# ECM3531 register map
Vendor: EtaCompute; Series: ECM35xx; File version: 1.0.0
CPU: CM3 r1p1, little endian, MPU, no FPU, 3 interrupt priority bits
Registers are 32-bit, read-write, reset 0x0 unless marked. A register's access mark holds for its fields unless they carry their own. Offsets are from the block's base; [hi:lo] are bit positions.

## SOCCTRL — The system control module provides memory mapped I/O control and status for various and miscellaneous portions of the SOC.
Base 0x50030080
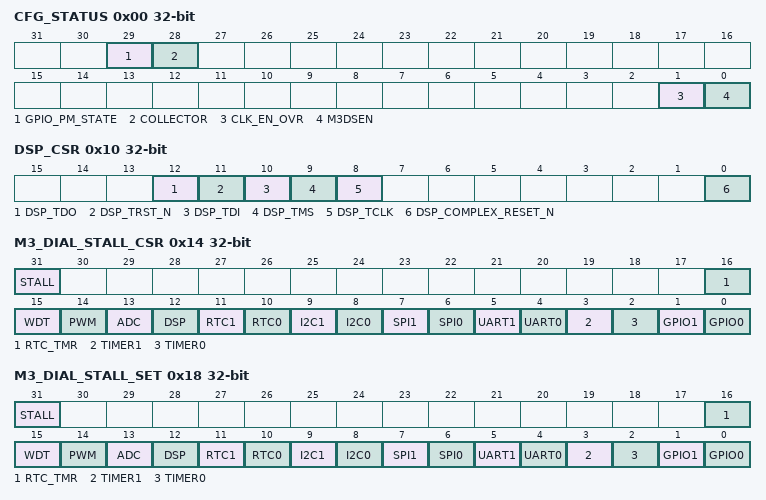
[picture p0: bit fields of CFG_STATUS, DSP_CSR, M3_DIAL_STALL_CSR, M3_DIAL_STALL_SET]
0x00 CFG_STATUS — Configuration and status bits for the SOCCTRL register.
  [29] GPIO_PM_STATE ro — Read only view of the pin state for the GPIO_PM pin. When this is one, then the chip is in one of its pin based test modes.
    0=NORMAL (Pins are all zero for normal mode. Anything else is abbienormal.); 1=ABNORMAL (Pins are in use for one of several test modes. GPIO, SPI1, SPI2, I2C1, I2C2, and UART1 do not work in this case.)
  [28] COLLECTOR ro — Read only view of internal debug state.
  [1] CLK_EN_OVR — Force the clock enable for this module ON to prevent clock gating at the HFO. Intended for debug purposes.
    1=ENABLE (Prevent HFO clock gating.); 0=DISABLE (Allow HFO clock gating when block is inactive.)
  [0] M3DSEN — Set to 1 to enable testing the whatchamacallit.
    1=ENABLE (Enable DIAL STALL of M3); 0=DISABLE (Disable DIAL STALLs for the M3 for testing.)
0x04 FLASH_CFG_STATUS — Configuration and status bits for the FLASH controller.
  [2:0] NUM_WS — Programmable number of wait states for the Flash Interface from the ARM M3.
0x08 M3_FREQ_COUNT — Provide a read only value for diagnostics.
  [31:0] COUNT ro — Debug Read Only Value M3 CLOCK frequency counter.
0x0C HFO_FREQ_COUNT — Provide a read only value for diagnostics.
  [31:0] COUNT ro — Debug Read Only Value HFO frequency counter.
0x10 DSP_CSR — Configuration and status bits for controlling the DSP.
  [12] DSP_TDO ro — Bit bang interface for DSP JTAG.
  [11] DSP_TRST_N — Bit bang interface for DSP JTAG. NOTE the inversion.
  [10] DSP_TDI — Bit bang interface for DSP JTAG.
  [9] DSP_TMS — Bit bang interface for DSP JTAG.
  [8] DSP_TCLK — Bit bang interface for DSP JTAG.
  [0] DSP_COMPLEX_RESET_N — Set to 0 to reset the DSP using the hard reset input to its DIAL block.
    0=FORCE (Force reset to the DSP.); 1=RELEASE (Release the master reset.)
0x14 M3_DIAL_STALL_CSR — Configuration and status bits for controlling DIAL stalls in the M3
  [31] STALL — Set to 1 to force the M3 into a DIAL STALL condition. In this state, the M3 is held in wait state much like clock gating sleep in conventional clocked logic. The normal NULL/DATA cycling is suspended until this flip flop is reset. It is reset upon the arrival of an enabled interrupt request to the M3, as enabled by the bits in this register. This FF can be set by the arrival of a WFI_TOGGLE from the M3 core. Use DIAL_STALL_SET and DIAL_STALL_CLR registers to manipulate this bit.
  [16] RTC_TMR — Set to 1 to enable the corresponding external interrupt to wake up the M3 core from a DIAL STALL state. Use DIAL_STALL_SET and DIAL_STALL_CLR registers to manipulate these bits.
  [15] WDT — Set to 1 to enable the corresponding external interrupt to wake up the M3 core from a DIAL STALL state. Use DIAL_STALL_SET and DIAL_STALL_CLR registers to manipulate these bits.
  [14] PWM — Set to 1 to enable the corresponding external interrupt to wake up the M3 core from a DIAL STALL state. Use DIAL_STALL_SET and DIAL_STALL_CLR registers to manipulate these bits.
  [13] ADC — Set to 1 to enable the corresponding external interrupt to wake up the M3 core from a DIAL STALL state. Use DIAL_STALL_SET and DIAL_STALL_CLR registers to manipulate these bits.
  [12] DSP — Set to 1 to enable the corresponding external interrupt to wake up the M3 core from a DIAL STALL state. Use DIAL_STALL_SET and DIAL_STALL_CLR registers to manipulate these bits.
  [11] RTC1 — Set to 1 to enable the corresponding external interrupt to wake up the M3 core from a DIAL STALL state. Use DIAL_STALL_SET and DIAL_STALL_CLR registers to manipulate these bits.
  [10] RTC0 — Set to 1 to enable the corresponding external interrupt to wake up the M3 core from a DIAL STALL state. Use DIAL_STALL_SET and DIAL_STALL_CLR registers to manipulate these bits.
  [9] I2C1 — Set to 1 to enable the corresponding external interrupt to wake up the M3 core from a DIAL STALL state. Use DIAL_STALL_SET and DIAL_STALL_CLR registers to manipulate these bits.
  [8] I2C0 — Set to 1 to enable the corresponding external interrupt to wake up the M3 core from a DIAL STALL state. Use DIAL_STALL_SET and DIAL_STALL_CLR registers to manipulate these bits.
  [7] SPI1 — Set to 1 to enable the corresponding external interrupt to wake up the M3 core from a DIAL STALL state. Use DIAL_STALL_SET and DIAL_STALL_CLR registers to manipulate these bits.
  [6] SPI0 — Set to 1 to enable the corresponding external interrupt to wake up the M3 core from a DIAL STALL state. Use DIAL_STALL_SET and DIAL_STALL_CLR registers to manipulate these bits.
  [5] UART1 — Set to 1 to enable the corresponding external interrupt to wake up the M3 core from a DIAL STALL state. Use DIAL_STALL_SET and DIAL_STALL_CLR registers to manipulate these bits.
  [4] UART0 — Set to 1 to enable the corresponding external interrupt to wake up the M3 core from a DIAL STALL state. Use DIAL_STALL_SET and DIAL_STALL_CLR registers to manipulate these bits.
  [3] TIMER1 — Set to 1 to enable the corresponding external interrupt to wake up the M3 core from a DIAL STALL state. Use DIAL_STALL_SET and DIAL_STALL_CLR registers to manipulate these bits.
  [2] TIMER0 — Set to 1 to enable the corresponding external interrupt to wake up the M3 core from a DIAL STALL state. Use DIAL_STALL_SET and DIAL_STALL_CLR registers to manipulate these bits.
  [1] GPIO1 — Set to 1 to enable the corresponding external interrupt to wake up the M3 core from a DIAL STALL state. Use DIAL_STALL_SET and DIAL_STALL_CLR registers to manipulate these bits.
  [0] GPIO0 — Set to 1 to enable the corresponding external interrupt to wake up the M3 core from a DIAL STALL state. Use DIAL_STALL_SET and DIAL_STALL_CLR registers to manipulate these bits.
0x18 M3_DIAL_STALL_SET — Bit setting for the configuration and status bits for controlling DIAL stalls in the M3
  [31] STALL wo — Set to 1 to cause the corresponding bit in the M3 DIAL STALL CSR to be set.
  [16] RTC_TMR — Set to 1 to enable the corresponding external interrupt to wake up the M3 core from a DIAL STALL state.
  [15] WDT — Set to 1 to enable the corresponding external interrupt to wake up the M3 core from a DIAL STALL state.
  [14] PWM — Set to 1 to enable the corresponding external interrupt to wake up the M3 core from a DIAL STALL state.
  [13] ADC — Set to 1 to enable the corresponding external interrupt to wake up the M3 core from a DIAL STALL state.
  [12] DSP — Set to 1 to enable the corresponding external interrupt to wake up the M3 core from a DIAL STALL state.
  [11] RTC1 — Set to 1 to enable the corresponding external interrupt to wake up the M3 core from a DIAL STALL state.
  [10] RTC0 — Set to 1 to enable the corresponding external interrupt to wake up the M3 core from a DIAL STALL state.
  [9] I2C1 — Set to 1 to enable the corresponding external interrupt to wake up the M3 core from a DIAL STALL state.
  [8] I2C0 — Set to 1 to enable the corresponding external interrupt to wake up the M3 core from a DIAL STALL state.
  [7] SPI1 — Set to 1 to enable the corresponding external interrupt to wake up the M3 core from a DIAL STALL state.
  [6] SPI0 — Set to 1 to enable the corresponding external interrupt to wake up the M3 core from a DIAL STALL state.
  [5] UART1 — Set to 1 to enable the corresponding external interrupt to wake up the M3 core from a DIAL STALL state.
  [4] UART0 — Set to 1 to enable the corresponding external interrupt to wake up the M3 core from a DIAL STALL state.
  [3] TIMER1 — Set to 1 to enable the corresponding external interrupt to wake up the M3 core from a DIAL STALL state.
  [2] TIMER0 — Set to 1 to enable the corresponding external interrupt to wake up the M3 core from a DIAL STALL state.
  [1] GPIO1 — Set to 1 to enable the corresponding external interrupt to wake up the M3 core from a DIAL STALL state.
  [0] GPIO0 — Set to 1 to enable the corresponding external interrupt to wake up the M3 core from a DIAL STALL state.
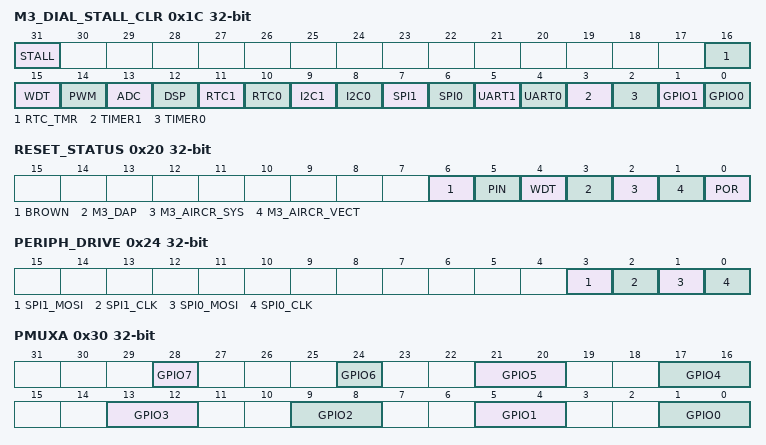
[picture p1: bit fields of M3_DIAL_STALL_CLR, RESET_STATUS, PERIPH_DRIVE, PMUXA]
0x1C M3_DIAL_STALL_CLR — Bit clearing for the configuration and status bits for controlling DIAL stalls in the M3
  [31] STALL wo — Set to 1 to cause the corresponding bit in the M3 DIAL STALL CSR to be cleared.
  [16] RTC_TMR — Set to 1 to disable the corresponding external interrupt from waking up the M3 core from a DIAL STALL state.
  [15] WDT — Set to 1 to disable the corresponding external interrupt from waking up the M3 core from a DIAL STALL state.
  [14] PWM — Set to 1 to disable the corresponding external interrupt from waking up the M3 core from a DIAL STALL state.
  [13] ADC — Set to 1 to disable the corresponding external interrupt from waking up the M3 core from a DIAL STALL state.
  [12] DSP — Set to 1 to disable the corresponding external interrupt from waking up the M3 core from a DIAL STALL state.
  [11] RTC1 — Set to 1 to disable the corresponding external interrupt from waking up the M3 core from a DIAL STALL state.
  [10] RTC0 — Set to 1 to disable the corresponding external interrupt from waking up the M3 core from a DIAL STALL state.
  [9] I2C1 — Set to 1 to disable the corresponding external interrupt from waking up the M3 core from a DIAL STALL state.
  [8] I2C0 — Set to 1 to disable the corresponding external interrupt from waking up the M3 core from a DIAL STALL state.
  [7] SPI1 — Set to 1 to disable the corresponding external interrupt from waking up the M3 core from a DIAL STALL state.
  [6] SPI0 — Set to 1 to disable the corresponding external interrupt from waking up the M3 core from a DIAL STALL state.
  [5] UART1 — Set to 1 to disable the corresponding external interrupt from waking up the M3 core from a DIAL STALL state.
  [4] UART0 — Set to 1 to disable the corresponding external interrupt from waking up the M3 core from a DIAL STALL state.
  [3] TIMER1 — Set to 1 to disable the corresponding external interrupt from waking up the M3 core from a DIAL STALL state.
  [2] TIMER0 — Set to 1 to disable the corresponding external interrupt from waking up the M3 core from a DIAL STALL state.
  [1] GPIO1 — Set to 1 to disable the corresponding external interrupt from waking up the M3 core from a DIAL STALL state.
  [0] GPIO0 — Set to 1 to disable the corresponding external interrupt from waking up the M3 core from a DIAL STALL state.
0x20 RESET_STATUS — Provide a read only view of status bits that get set by the various causes for an SOC reset. Writing anything to this register resets all the bits. The bits can accumulate so it is possible to have both the POR and M3_DAP bits set immediately after a reset caused by the debugger, for example. POR will always clear the other status bits as will writing to this regiser.
  [6] BROWN ro — Set to one if and only if a brownout reset occurred, since the last time this bit was cleared. This bit is cleared by writing anything to this register. NOTE: This is not currently implemented in the chip.
  [5] PIN ro — Set to one if and only if the hardware reset pin was asserted since the last time this bit was cleared. This bit is cleared by writing anything to this register.
  [4] WDT ro — Set to one if and only if the watchdog timer expired with reset enabled, since the last time this bit was cleared. This bit is cleared by writing anything to this register.
  [3] M3_DAP ro — Set to one if and only if the M3 DAP CSR bit in the M3 was written to 1 since the last time this bit was cleared. This bit is cleared by writing anything to this register.
  [2] M3_AIRCR_SYS ro — Set to one if and only if the AIRCR SYSTEM RESET REQUEST bit in the M3 was written to 1 since the last time this bit was cleared. This bit is cleared by writing anything to this register. This bit resets the entire chip.
  [1] M3_AIRCR_VECT ro — Set to one if and only if the AIRCR VECTOR RESET REQUEST bit in the M3 was written to 1 since the last time this bit was cleared. This bit is cleared by writing anything to this register. This bit only resets the M3 core.
  [0] POR ro — Set to one if and only if the power on reset pin was asserted since the last time this bit was cleared. This bit is cleared by writing anything to this register.
0x24 PERIPH_DRIVE — Controls the high drive strength settings for some of the dedicated pads associated with various peripherals, e.g. SPI clock.
  [3] SPI1_MOSI — Debug Read Only Value for Diagnostics.
  [2] SPI1_CLK — Debug Read Only Value for Diagnostics.
  [1] SPI0_MOSI — Debug Read Only Value for Diagnostics.
  [0] SPI0_CLK — Debug Read Only Value for Diagnostics.
0x28 FWTRACEA — Provide software driven output that can be seen on the front panel without a UART, etc.
  [31:0] VALUE — Firmware can write to this register and the results will show up on the front panel.NOTE: this register only gets cleared by the initial power on reset and not by anyother form of reset.
0x2C FWTRACEB — Provide software driven output that can be seen on the front panel without a UART, etc. NOTE: this register only gets cleared by the initial power on reset and not by anyother form of reset.
  [31:0] VALUE — Firmware can write to this register and the results will show up on the front panel.
0x30 PMUXA — This register provides control pin/pad mux for GPIO[7:0]
  [28] GPIO7 — Selects one of 4 possible uses for this pin.
    0=GPIO7 (GPIO7 in normal mode); 1=PWMCH7 (PWM Channel 7 in normal mode)
  [24] GPIO6 — Selects one of 4 possible uses for this pin.
    0=GPIO6 (GPIO6 in normal mode); 1=PWMCH6 (PWM Channel 6 in normal mode)
  [21:20] GPIO5 — Selects one of 4 possible uses for this pin.
    0=GPIO5 (GPIO5 in normal mode); 1=PWMCH5 (PWM Channel 5 in normal mode); 2=UART1DBGA (UART1 DEBUG A output in normal mode)
  [17:16] GPIO4 — Selects one of 4 possible uses for this pin.
    0=GPIO4 (GPIO4 in normal mode); 1=PWMCH4 (PWM Channel 4 in normal mode); 2=UART1DBGB (UART1 DEBUG B output in normal mode)
  [13:12] GPIO3 — Selects one of 4 possible uses for this pin.
    0=GPIO3 (GPIO3 in normal mode); 1=PWMCH3 (PWM Channel 3 in normal mode); 2=UART1DBGC (UART1 DEBUG C output in normal mode)
  [9:8] GPIO2 — Selects one of 4 possible uses for this pin.
    0=GPIO2 (GPIO2 in normal mode); 1=PWMCH2 (PWM Channel 2 in normal mode); 2=UART0DBGA (UART0 DEBUG A output in normal mode)
  [5:4] GPIO1 — Selects one of 4 possible uses for this pin.
    0=GPIO1 (GPIO1 in normal mode); 1=PWMCH1 (PWM Channel 1 in normal mode); 2=UART0DBGB (UART0 DEBUG B output in normal mode)
  [1:0] GPIO0 — Selects one of 4 possible uses for this pin.
    0=GPIO0 (GPIO0 in normal mode); 1=PWMCH0 (PWM Channel 0 in normal mode); 2=UART0DBGC (UART0 DEBUG C output in normal mode)
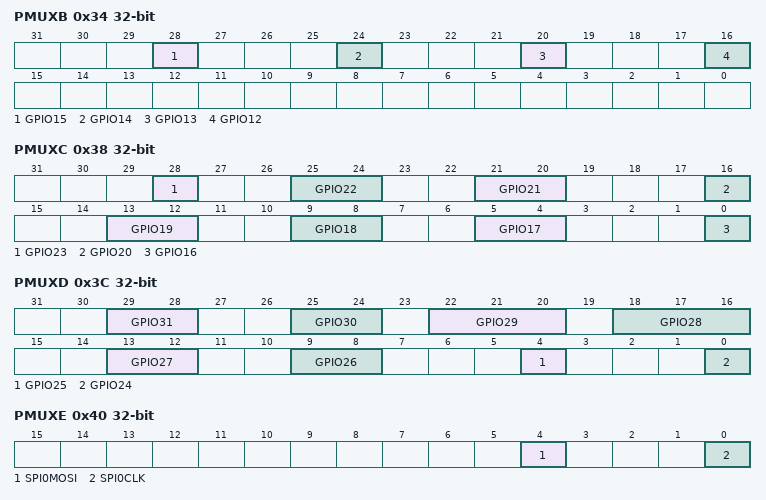
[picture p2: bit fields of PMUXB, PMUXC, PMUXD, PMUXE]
0x34 PMUXB — This register provides control pin/pad mux for GPIO[15:8]
  [28] GPIO15 — Selects one of 2 possible uses for this pin.
    0=GPIO15 (GPIO15 in normal mode); 1=I2S_DATA_IN (I2S Data Input in normal mode)
  [24] GPIO14 — Selects one of 2 possible uses for this pin.
    0=GPIO14 (GPIO14 in normal mode); 1=I2S_LRCLK (I2S Left/Right Frame Clock.)
  [20] GPIO13 — Selects one of 2 possible uses for this pin.
    0=GPIO13 (GPIO13 in normal mode); 1=I2S_BCLK (I2S Bit Clock)
  [16] GPIO12 — Selects one of 2 possible uses for this pin.
    0=GPIO12 (GPIO12 in normal mode); 1=I2S_ACLK (I2S ACLK (24.576MHz) in normal mode)
0x38 PMUXC — This register provides control pin/pad mux for GPIO[23:16]
  [28] GPIO23 — Selects one of 2 possible uses for this pin.
    0=GPIO23 (GPIO23 in normal mode); 1=SPI0CS0 (SPI0 Chip Select 0 in normal mode)
  [25:24] GPIO22 — Selects one of 3 possible uses for this pin.
    0=GPIO22 (GPIO22 in normal mode); 1=UART1RTS (UART1 RTS pin.); 2=DSP_JTAG_TDO (DSP JTAG TDO ouput pin.)
  [21:20] GPIO21 — Selects one of 3 possible uses for this pin.
    0=GPIO21 (GPIO21 in normal mode); 1=UART1CTS (UART1 CTS pin.); 2=DSP_JTAG_TCLK (DSP JTAG TCLK input.)
  [16] GPIO20 — Selects one of 2 possible uses for this pin.
    0=GPIO20 (GPIO20 in normal mode); 1=UART1TX (UART1 TX pin.)
  [13:12] GPIO19 — Selects one of 3 possible uses for this pin.
    0=GPIO19 (GPIO19 in normal mode); 1=UART1RX (UART1 RX pin.); 2=DSP_JTAG_TRST_N (DSP JTAG TRST_N input.)
  [9:8] GPIO18 — Selects one of 2 possible uses for this pin.
    0=GPIO18 (GPIO18 in normal mode); 2=DSP_JTAG_TDI (DSP JTAG TDI INPUT)
  [5:4] GPIO17 — Selects one of 2 possible uses for this pin.
    0=GPIO17 (GPIO17 in normal mode); 2=DSP_JTAG_TMS (DSP JTAG TMS INPUT)
  [0] GPIO16 — Selects one of 2 possible uses for this pin.
    0=GPIO16 (GPIO16 in normal mode); 1=I2S_DATA_OUT (I2S Data Output pin.)
0x3C PMUXD — This register provides control pin/pad mux for GPIO[31:24]
  [29:28] GPIO31 — Selects one of 4 possible uses for this pin.
    0=GPIO31 (GPIO31 in normal mode); 1=SPI1CS1 (SPI1 Chip Select 1); 2=SPI1RDY (SPI1 Ready); 3=SPI2CS1 (SPI1 Chip Select 2)
  [25:24] GPIO30 — Selects one of 4 possible uses for this pin.
    0=GPIO30 (GPIO30 in normal mode); 1=SPI1CS0 (SPI1 chip select 0.); 2=SPI2RDY (SPI2 Ready); 3=SPI2CS0 (SPI2 chip select 0.)
  [22:20] GPIO29 — Selects one of 5 possible uses for this pin.
    0=GPIO29 (GPIO29 in normal mode); 1=SPI1CLK (SPI1 Clock pin); 2=I2C1SCK (I2C1 Clock pin); 3=SPI2CLK (SPI1 Clock pin); 4=I2C2SCK (I2C2 Clock pin)
  [18:16] GPIO28 — Selects one of 5 possible uses for this pin.
    0=GPIO28 (GPIO28 in normal mode); 1=SPI1MOSI (SPI1 MOSI pin); 2=I2C1SDA (I2C1 SDATA pin); 3=SPI2MOSI (SPI1 MOSI pin); 4=I2C2SDA (I2C2 SDATA pin)
  [13:12] GPIO27 — Selects one of 3 possible uses for this pin.
    0=GPIO27 (GPIO27 in normal mode); 1=SPI1MISO (SPI1 MISO pin.); 3=SPI2MISO (SPI2 MISO pin.)
  [9:8] GPIO26 — Selects one of 3 possible uses for this pin.
    0=GPIO26 (GPIO26 in normal mode); 1=SPI0CS3 (SPI0 Chip Select 3); 2=SPI0RDY (SPI0 ready input.)
  [4] GPIO25 — Selects one of 2 possible uses for this pin.
    0=GPIO25 (GPIO25 in normal mode); 1=SPI0CS2 (SPI0 Chip Select 2)
  [0] GPIO24 — Selects one of 2 possible uses for this pin.
    0=GPIO24 (GPIO24 in normal mode); 1=SPI0CS1 (SPI0 Chip Select 1)
0x40 PMUXE — This register provides control pin/pad mux for SPI0
  [4] SPI0MOSI — Selects one of 2 possible uses for this pin.
    0=MOSI (SPI0 Clock in SPI mode); 1=I2C0SDA (I2C0 DATA in I2C mode)
  [0] SPI0CLK — Selects one of 2 possible uses for this pin.
    0=SPI0CLK (SPI0 Clock in SPI mode); 1=I2C0SCK (I2C0 Clock in I2C mode)
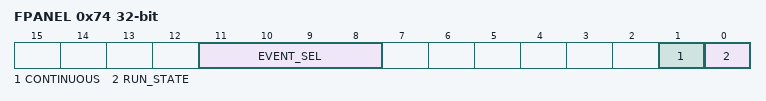
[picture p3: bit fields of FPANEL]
0x74 FPANEL — This register provides control over a few functions in the front panel and the INSTR_STOP pin.
  [11:8] EVENT_SEL — Selects one of 16 event sources into the event counter.
  [1] CONTINUOUS — Set to 1 to launch continuously, i.e. restart immediately after the last spew.
    1=ALWAYS (Always restart immediately.); 0=LAUNCHED (Use 1Hz clock to launch.)
  [0] RUN_STATE — Set to 1 to stop the front panel.
    0=HALT (stop the front panel to save power.); 1=RUN (let the front panel run (default).)
0x7C DEBUG_READ_ONLY — Provide a read only value for diagnostics.
  [31:0] VALUE ro — Debug Read Only Value for Diagnostics.
